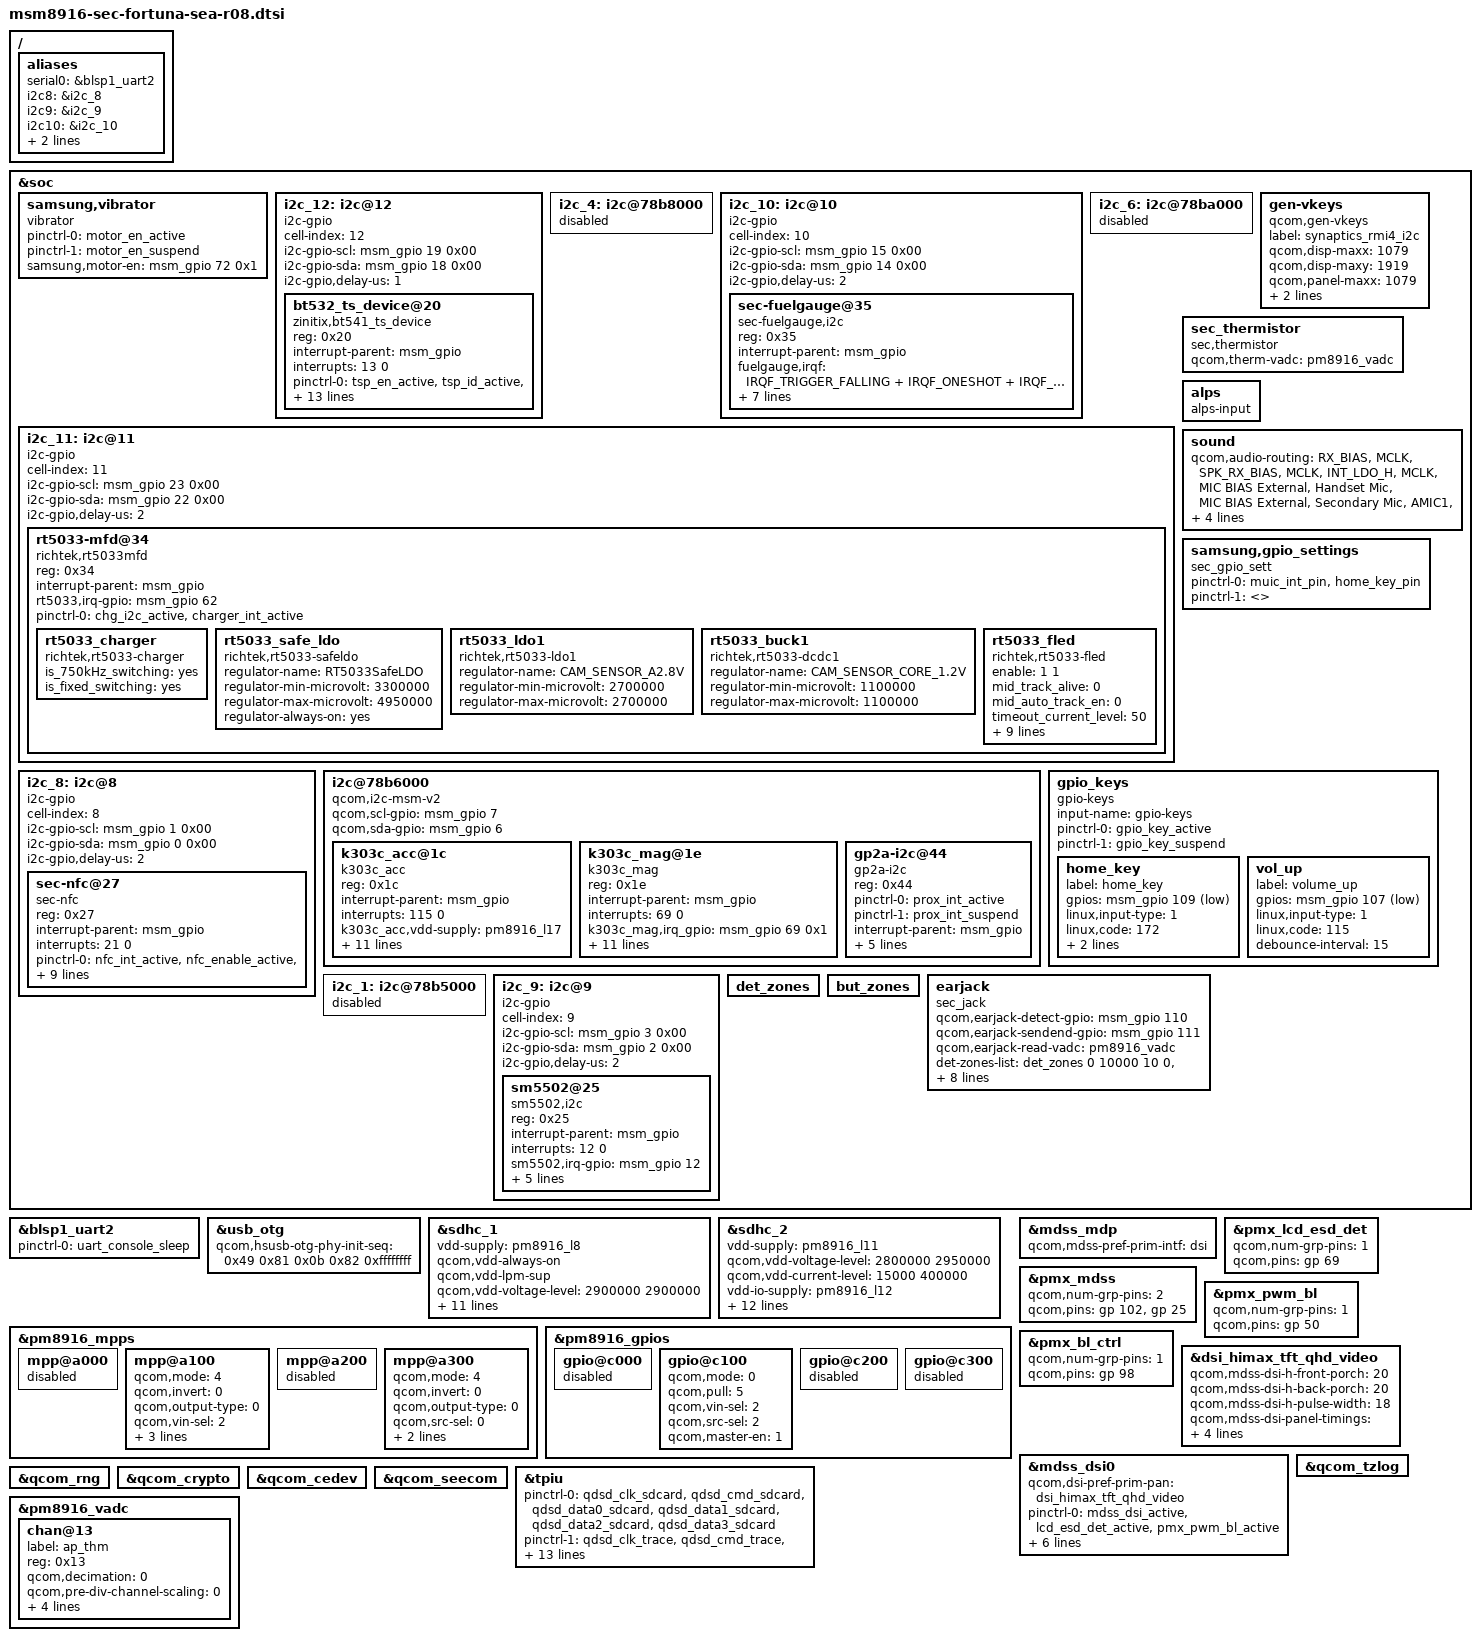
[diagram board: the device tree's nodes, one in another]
/* Copyright (c) 2014, The Linux Foundation. All rights reserved.
 *
 * This program is free software; you can redistribute it and/or modify
 * it under the terms of the GNU General Public License version 2 and
 * only version 2 as published by the Free Software Foundation.
 *
 * This program is distributed in the hope that it will be useful,
 * but WITHOUT ANY WARRANTY; without even the implied warranty of
 * MERCHANTABILITY or FITNESS FOR A PARTICULAR PURPOSE.  See the
 * GNU General Public License for more details.
 */

#include "msm8916.dtsi"
#include "msm8916-pinctrl-sec-fortuna-sea-r08.dtsi"
#include "dsi_panel_hx8389c_tft_qhd_video.dtsi"
#include "msm8916-camera.dtsi"
#include "msm8916-camera-sensor-cdp-r02.dtsi"
#include "msm8916-sec-fortuna-battery-r01.dtsi"

/ {
	aliases {
		serial0 = &blsp1_uart2;

		/*i2c-gpio bus_id*/
              //i2c7 = &i2c_7;
                i2c8 = &i2c_8;
		i2c9 = &i2c_9;
		i2c10 = &i2c_10;
		i2c11 = &i2c_11;
		i2c12 = &i2c_12;
	};
};

&soc {
	samsung,vibrator {
		pinctrl-names = "tlmm_motor_en_active","tlmm_motor_en_suspend";
		pinctrl-0 = <&motor_en_active>;
		pinctrl-1 = <&motor_en_suspend>;
		compatible = "vibrator";
		samsung,motor-en = <&msm_gpio 72 0x1>;
		status = "ok";
	};

	i2c_12:i2c@12 {
		cell-index = <12>;
		compatible = "i2c-gpio";
		i2c-gpio-scl = <&msm_gpio 19 0x00>;
		i2c-gpio-sda = <&msm_gpio 18 0x00>;
		i2c-gpio,delay-us = <1>;
		#address-cells = <1>;
		#size-cells = <0>;

		bt532_ts_device@20 {
			compatible = "zinitix,bt541_ts_device";
			reg = <0x20>;
			interrupt-parent = <&msm_gpio>;
			interrupts = <13 0>;
			pinctrl-names = "tsp_en_gpio_active", "tsp_en_gpio_suspend";
			pinctrl-0 = <&tsp_en_active &tsp_id_active &int_active &tsp_i2c_active>;
			pinctrl-1 = <&tsp_en_suspend &tsp_id_suspend &tsp_i2c_sleep>;
			vddo-supply = <&pm8916_l6>;
			zinitix,vdd_en-gpio = <&msm_gpio 73 0x01>;
			tsp_id-gpio =  <&msm_gpio 56 0x01>;
			zinitix,irq-gpio = <&msm_gpio 13 0x00>;
			zinitix,x_resolution = <540>;
			zinitix,y_resolution = <960>;
			zinitix,page_size = <128>;
			zinitix,orientation = <0>;
			zinitix,tsp_vdd_supply_type = <0>;
			zinitix,pname = "SM-G5308W";
		};
	};

	i2c_4: i2c@78b8000 { /* BLSP1 QUP4 */
		status="disable";
	};

       i2c_10:i2c@10 {
		cell-index = <10>;
		compatible = "i2c-gpio";
		i2c-gpio-scl = <&msm_gpio 15 0x00>;
		i2c-gpio-sda = <&msm_gpio 14 0x00>;
		i2c-gpio,delay-us = <2>;
		#address-cells = <1>;
		#size-cells = <0>;

		sec-fuelgauge@35{
			compatible = "sec-fuelgauge,i2c";
			reg = <0x35>;
			interrupt-parent = <&msm_gpio>;
			fuelgauge,irqf = "IRQF_TRIGGER_FALLING + IRQF_ONESHOT + IRQF_NO_SUSPEND";
			fuelgauge,fuel_int = <&msm_gpio 121 0x1>;
			pinctrl-names = "default";
			pinctrl-0 = <&fg_i2c_active &fuel_int_active>;

			fuelgauge,capacity_max = <1000>;
			fuelgauge,capacity_max_margin = <50>;
			fuelgauge,capacity_min = <0>;
			fuelgauge,capacity_calculation_type = <0x17>;
			fuelgauge,fuel_alert_soc = <1>;
		};
	};

	i2c_6: i2c@78ba000 { /* BLSP1 QUP6 */
		status="disable";
	};

       i2c_11:i2c@11 {
		cell-index = <11>;
		compatible = "i2c-gpio";
		i2c-gpio-scl = <&msm_gpio 23 0x00>;
		i2c-gpio-sda = <&msm_gpio 22 0x00>;
		i2c-gpio,delay-us = <2>;
		#address-cells = <1>;
		#size-cells = <0>;

		rt5033-mfd@34{
			compatible = "richtek,rt5033mfd";
			reg = <0x34>;
			interrupt-parent = <&msm_gpio>;
			rt5033,irq-gpio = <&msm_gpio 62 0x00>;
			pinctrl-names = "default";
			pinctrl-0 = <&chg_i2c_active &charger_int_active>;

			rt5033_charger {
				compatible = "richtek,rt5033-charger";
				is_750kHz_switching = "yes";
				is_fixed_switching = "yes";
			};

			rt5033_safe_ldo {
				compatible = "richtek,rt5033-safeldo";
				regulator-name = "RT5033SafeLDO"; /* constraints->name, change name by yourself*/
				regulator-min-microvolt = <3300000>;
				regulator-max-microvolt = <4950000>; /* if max == min then apply_uV = 1 */
				/* regulator-microvolt-offset = <0>; optional*/
				/* regulator-boot-on = "yes"; optional, exist = enabled */
				regulator-always-on = "yes";
				/* regulator-ramp-delay = <100>; optional*/
			};

			rt5033_ldo1 {
				compatible = "richtek,rt5033-ldo1";
				regulator-name = "CAM_SENSOR_A2.8V"; /* change name by yourself */
				regulator-min-microvolt = <2700000>;
				regulator-max-microvolt = <2700000>; /* max == min then apply_uV = 1 */
				/* regulator-microvolt-offset = < >; optional*/
				/* regulator-boot-on = "yes"; optional, exist = enabled */
				/* regulator-always-on = "yes"; optional, exist = enabled */
				/* regulator-ramp-delay = <100>; optional*/

			};


			rt5033_buck1 {
				compatible = "richtek,rt5033-dcdc1";
				regulator-name = "CAM_SENSOR_CORE_1.2V"; /* change name by yourself */
				regulator-min-microvolt = <1100000>;
				regulator-max-microvolt = <1100000>; /* max == min then apply_uV = 1 */
				/* regulator-microvolt-offset = < >; optional*/
				/* regulator-boot-on = "yes"; optional, exist = enabled */
				/* regulator-always-on = "yes"; optional, exist = enabled */
				/* regulator-ramp-delay = <100>; optional*/

			};

			rt5033_fled {
				compatible = "richtek,rt5033-fled";
				enable = <1 1>;
				mid_track_alive = <0>;
				mid_auto_track_en = <0>;
				timeout_current_level = <50>;
				strobe_current = <500>;
				strobe_timeout = <544>;
				torch_current = <63>;
				lv_protection = <3000>;
				mid_level = <4400>;
				rt5033,led1-gpio = <&msm_gpio 34 0x00>;
				rt5033,led2-gpio = <&msm_gpio 36 0x00>;
				pinctrl-names = "fled_default","fled_sleep";
				pinctrl-0 = <&cam_flash_active>;
				pinctrl-1 = <&cam_flash_sleep>;
			};
		};
	};

	gen-vkeys {
		compatible = "qcom,gen-vkeys";
		label = "synaptics_rmi4_i2c";
		qcom,disp-maxx = <1079>;
		qcom,disp-maxy = <1919>;
		qcom,panel-maxx = <1079>;
		qcom,panel-maxy = <2084>;
		qcom,key-codes = <158 139 172 217>;
	};

	sec_thermistor {
		compatible = "sec,thermistor";
		qcom,therm-vadc = <&pm8916_vadc>;
	};

	alps {
			compatible = "alps-input";
	};

	i2c_8: i2c@8 {
		cell-index = <8>;
		compatible = "i2c-gpio";
		i2c-gpio-scl = <&msm_gpio 1 0x00>;
		i2c-gpio-sda = <&msm_gpio 0 0x00>;
		i2c-gpio,delay-us = <2>;
		#address-cells = <1>;
		#size-cells = <0>;
		sec-nfc@27 {
			compatible = "sec-nfc";
			reg = <0x27>;
			interrupt-parent = <&msm_gpio>;
			interrupts = <21 0>;
			pinctrl-names = "default","nfc_suspend";
			pinctrl-0 = <&nfc_int_active &nfc_enable_active &nfc_firmware_active &nfc_i2c_active>;
			pinctrl-1 = <&nfc_int_suspend &nfc_enable_suspend &nfc_firmware_suspend &nfc_i2c_suspend>;
			sec-nfc,firm-gpio = <&msm_gpio 49 0x01>;
			sec-nfc,ven-gpio = <&msm_gpio 20 0x01>;
			sec-nfc,irq-gpio = <&msm_gpio 21 0x00>;
			clocks = <&clock_rpm clk_bb_clk2_pin>;
			clock-names = "nfc_clock";
			nfc_ldo-supply = <&pm8916_l14>;
		};
	};

	i2c@78b6000 { /* BLSP1 QUP2 */
		compatible = "qcom,i2c-msm-v2";
		qcom,scl-gpio = <&msm_gpio 7 0>;
		qcom,sda-gpio = <&msm_gpio 6 0>;
		k303c_acc@1c {
			compatible = "k303c_acc";
			reg = <0x1c>;
			interrupt-parent = <&msm_gpio>;
			interrupts = <115 0>;
			k303c_acc,vdd-supply = <&pm8916_l17>;
			k303c_acc,vio-supply = <&pm8916_l5>;
			k303c_acc,gpio_int1 = <&msm_gpio 115 0x00>;
			k303c_acc,poll_interval = <100>;
			k303c_acc,min_interval = <2>;
			k303c_acc,fs_range = <0x00>;
			k303c_acc,axis_map_x = <0>;
			k303c_acc,axis_map_y = <1>;
			k303c_acc,axis_map_z = <2>;
			k303c_acc,negate_x = <1>;
			k303c_acc,negate_y = <0>;
			k303c_acc,negate_z = <0>;
		};
		k303c_mag@1e {
			compatible = "k303c_mag";
			reg = <0x1e>;
			interrupt-parent = <&msm_gpio>;
			interrupts = <69 0>;
			k303c_mag,irq_gpio = <&msm_gpio 69 0x1>;
			k303c_mag,vdd-supply = <&pm8916_l17>;
			k303c_mag,vio-supply = <&pm8916_l5>;
			k303c_mag,poll_interval = <100>;
			k303c_mag,min_interval = <13>;
			k303c_mag,fs_range = <0x60>;
			k303c_mag,axis_map_x = <0>;
			k303c_mag,axis_map_y = <1>;
			k303c_mag,axis_map_z = <2>;
			k303c_mag,negate_x = <1>;
			k303c_mag,negate_y = <0>;
			k303c_mag,negate_z = <0>;
		};
		gp2a-i2c@44{
			compatible = "gp2a-i2c";
			reg = <0x44>;
			pinctrl-names = "default";
			pinctrl-0 = <&prox_int_active>;
			pinctrl-1 = <&prox_int_suspend>;
			interrupt-parent = <&msm_gpio>;
			interupts= <113 0>;
			gp2a-i2c,irq-gpio = <&msm_gpio 113 0x00>;
			gp2a-i2c,en-gpio = <&msm_gpio 8 0x00>;
			gp2a-vdd-supply = <&pm8916_l17>;
			gp2a-vio-supply = <&pm8916_l5>;
		};
	};

	/* Over-riding model specific changes */
	sound {
		qcom,audio-routing =
			"RX_BIAS", "MCLK",
			"SPK_RX_BIAS", "MCLK",
			"INT_LDO_H", "MCLK",
			"MIC BIAS External", "Handset Mic",
			"MIC BIAS External", "Secondary Mic",
			"AMIC1", "MIC BIAS External",
			"AMIC2", "Headset Mic",
			"AMIC3", "MIC BIAS External";
		pinctrl-names = "cdc_lines_act",
				"cdc_lines_sus";
		pinctrl-0 = <&cdc_pdm_lines_act>;
		pinctrl-1 = <&cdc_pdm_lines_sus>;
	};

	samsung,gpio_settings{
		compatible = "sec_gpio_sett";
		pinctrl-names = "sec_gpio_active","sec_gpio_suspend";
		pinctrl-0 = <&muic_int_pin &home_key_pin>;
		pinctrl-1 = <>;
	};

};

&blsp1_uart2 {
	status = "ok";
	pinctrl-names = "default";
	pinctrl-0 = <&uart_console_sleep>;
};

&soc {
	gpio_keys {
		compatible = "gpio-keys";
		input-name = "gpio-keys";
		pinctrl-names = "tlmm_gpio_key_active","tlmm_gpio_key_suspend";
		pinctrl-0 = <&gpio_key_active>;
		pinctrl-1 = <&gpio_key_suspend>;

		home_key {
			label = "home_key";
			gpios = <&msm_gpio 109 0x1>;
			linux,input-type = <1>;
			linux,code = <172>;
			gpio-key,wakeup;
			debounce-interval = <15>;
		};
		vol_up {
			label = "volume_up";
			gpios = <&msm_gpio 107 0x1>;
			linux,input-type = <1>;
			linux,code = <115>;
			debounce-interval = <15>;
		};
	};

	i2c_1: i2c@78b5000 { /* BLSP1 QUP1 */
		status="disable";
	};

	i2c_9:i2c@9 { /*SM5502 GPIO-I2C*/
		cell-index = <9>;
		compatible = "i2c-gpio";
		i2c-gpio-scl = <&msm_gpio 3 0x00>;
		i2c-gpio-sda = <&msm_gpio 2 0x00>;
		i2c-gpio,delay-us = <2>;
		#address-cells = <1>;
		#size-cells = <0>;

		sm5502@25{
			compatible = "sm5502,i2c";
			reg = <0x25>;
			interrupt-parent = <&msm_gpio>;
			interrupts= <12 0>;
			sm5502,irq-gpio = <&msm_gpio 12 0x00>;
			sm5502,gpio-sda = <&msm_gpio 2 0x00>;
			sm5502,gpio-scl = <&msm_gpio 3 0x00>;
			sm5502,uarton-gpio = <&msm_gpio 114 0x00>;
			pinctrl-names = "sm5502_i2c_active","sm5502_i2c_suspend";
			pinctrl-0 = <&muic_i2c_active>;
			pinctrl-1 = <&muic_i2c_suspend>;
		};
	};

	det_zones: det_zones {
		#list-det-cells = <4>;
	};

	but_zones: but_zones {
		#list-but-cells = <3>;
	};

	earjack {
		compatible = "sec_jack";
		qcom,earjack-detect-gpio = <&msm_gpio 110 0x0>;
		qcom,earjack-sendend-gpio = <&msm_gpio 111 0x0>;
		qcom,earjack-read-vadc = <&pm8916_vadc>;

		det-zones-list = <&det_zones 0 10000 10 0>,
						 <&det_zones 975 10000 10 0>,
						 <&det_zones 976 10000 10 1>,
						 <&det_zones 1810 10000 10 1>;
		but-zones-list = <&but_zones 0 0 325>,
						 <&but_zones 1 326 457>,
						 <&but_zones 2 458 999>;
		mpp-channel-scaling = <2 1 1>;
		pinctrl-names = "earjack_gpio_active","earjack_gpio_suspend";
		pinctrl-0 = <&earjack_det_act &earjack_switch_act>;
		pinctrl-1 = <&earjack_det_sus &earjack_switch_sus>;
	};
};

&usb_otg {
	qcom,hsusb-otg-phy-init-seq =
					<0x49 0x81 0x0b 0x82 0xffffffff>;
};

&sdhc_1 {
	vdd-supply = <&pm8916_l8>;
	qcom,vdd-always-on;
	qcom,vdd-lpm-sup;
	qcom,vdd-voltage-level = <2900000 2900000>;
	qcom,vdd-current-level = <200 400000>;

	vdd-io-supply = <&pm8916_l5>;
	qcom,vdd-io-always-on;
	qcom,vdd-io-lpm-sup;
	qcom,vdd-io-voltage-level = <1800000 1800000>;
	qcom,vdd-io-current-level = <200 60000>;

	pinctrl-names = "active", "sleep";
	pinctrl-0 = <&sdc1_clk_on &sdc1_cmd_on &sdc1_data_on>;
	pinctrl-1 = <&sdc1_clk_off &sdc1_cmd_off &sdc1_data_off>;

	qcom,nonremovable;

	status = "ok";
};

&sdhc_2 {
	vdd-supply = <&pm8916_l11>;
	qcom,vdd-voltage-level = <2800000 2950000>;
	qcom,vdd-current-level = <15000 400000>;

	vdd-io-supply = <&pm8916_l12>;
	qcom,vdd-io-voltage-level = <1800000 2950000>;
	qcom,vdd-io-current-level = <200 50000>;

	pinctrl-names = "active", "sleep";
	pinctrl-0 = <&sdc2_clk_on &sdc2_cmd_on &sdc2_data_on &sdc2_cd_on>;
	pinctrl-1 = <&sdc2_clk_off &sdc2_cmd_off &sdc2_data_off &sdc2_cd_off>;

	#address-cells = <0>;
	interrupt-parent = <&sdhc_2>;
	interrupts = <0 1 2>;
	#interrupt-cells = <1>;
	interrupt-map-mask = <0xffffffff>;
	interrupt-map = <0 &intc 0 125 0
			1 &intc 0 221 0
			2 &msm_gpio 38 0>;
	interrupt-names = "hc_irq", "pwr_irq", "status_irq";
	cd-gpios = <&msm_gpio 38 0x1>;

	status = "ok";
};

&pm8916_mpps {
	mpp@a000 { /* MPP 1 */
		/* VDD_PX */
		status = "disabled";
	};

	mpp@a100 { /* MPP 2 */
		status = "ok";
		qcom,mode = <4>; // AIN input
		qcom,invert = <0>; //No Invert
		qcom,output-type = <0>; //CMOS
		qcom,vin-sel = <2>; //PM8971_S3 1.8v
		qcom,src-sel = <0>; //MPP Constant
		qcom,ain-route = <1>; // QPNP_PIN_AIN_AMUX_CH6 = 1 for MPP2
		qcom,master-en = <1>; // Function constant
	};

	mpp@a200 { /* MPP 3 */
		/* VREF DAC */
		status = "disabled";
	};

	mpp@a300 { /* MPP 4 */
		status = "ok";
		qcom,mode = <4>; // AIN input
		qcom,invert = <0>; //No Invert
		qcom,output-type = <0>; //CMOS
		qcom,src-sel = <0>; //MPP Constant
		qcom,ain-route = <3>; // QPNP_PIN_AIN_AMUX_CH8 = 3 for MPP4
		qcom,master-en = <1>; // Function constant
	};
};

&pm8916_gpios {
	gpio@c000 { /* GPIO 1 */
		/* Battery UICC Alarm */
		status = "disabled";
	};

	gpio@c100 { /* GPIO 2 */
		/* NFC_CLK_REQ */
		qcom,mode = <0>; /* QPNP_PIN_MODE_DIG_IN */
		qcom,pull = <5>; /* QPNP_PIN_PULL_NO */
		qcom,vin-sel = <2>; /* QPNP_PIN_VIN2 */
		qcom,src-sel = <2>; /* QPNP_PIN_SEL_FUNC_1 */
		qcom,master-en = <1>;
	};

	gpio@c200 { /* GPIO 3 */
		/* External regulator control for WTR */
		status = "disabled";
	};

	gpio@c300 { /* GPIO 4 */
		/* External regulator control for APC */
		status = "disabled";
	};
};

&mdss_mdp {
       qcom,mdss-pref-prim-intf = "dsi";
};

&pmx_lcd_esd_det {
	qcom,num-grp-pins = <1>;
	qcom,pins = <&gp 69>;
};

&pmx_mdss {
                 qcom,num-grp-pins = <2>;
                 qcom,pins = <&gp 102>, <&gp 25>;
};

&pmx_pwm_bl {
                 qcom,num-grp-pins = <1>;
                 qcom,pins = <&gp 50>;
};

&pmx_bl_ctrl {
                 qcom,num-grp-pins = <1>;
                 qcom,pins = <&gp 98>;
};

&dsi_himax_tft_qhd_video {
	qcom,mdss-dsi-h-front-porch = <20>;
	qcom,mdss-dsi-h-back-porch = <20>;
	qcom,mdss-dsi-h-pulse-width = <18>;
	qcom,mdss-dsi-panel-timings = [7B 1A 10 00 3E 40 16 1E 15 03 04 00];
	qcom,mdss-dsi-t-clk-pre = <0x1A>;
	qcom,mdss-dsi-on-command = [39 01 00 00 0A 00 04 B9 FF 83 89
				39 01 00 00 00 00 15 B1 7F 10 10 D2 32 80 10 F0 56 80 20 20 F8 AA AA A1 00 80 30 00
				39 01 00 00 00 00 0B B2 82 50 05 07 F0 38 11 64 5D 09
				39 01 00 00 00 00 0C B4 66 66 66 70 00 00 18 76 28 76 A8
				39 01 00 00 00 00 02 D2 33
				39 01 00 00 00 00 05 C0 30 17 00 03
				39 01 00 00 00 00 05 C7 00 80 00 C0
				39 01 00 00 0A 00 05 BF 05 50 00 3E
				39 01 00 00 00 00 04 B9 FF 83 89
				39 01 00 00 00 00 02 CC 0E
				39 01 00 00 00 00 24 D3 00 00 00 00 00 08 00 32 10 00 00 00 03 C6 03 C6 00 00 00 00 35 33 04 04 37 00 00 00 05 08 00 00 0A 00 01
				39 01 00 00 00 00 27 D5 18 18 18 18 19 19 18 18 20 21 24 25 18 18 18 18 00 01 04 05 02 03 06 07 18 18 18 18 18 18 18 18 18 18 18 18 18 18
				39 01 00 00 00 00 27 D6 18 18 18 18 18 18 19 19 25 24 21 20 18 18 18 18 07 06 03 02 05 04 01 00 18 18 18 18 18 18 18 18 18 18 18 18 18 18
				39 01 00 00 00 00 04 B7 20 80 00
				39 01 00 00 00 00 2B E0 00 02 06 38 3C 3F 1B 46 06 09 0C 17 10 13 16 13 14 08 13 15 19 00 02 06 37 3C 3F 1A 45 05 09 0B 16 0F 13 15 13 14 07 12 14 18
				39 01 00 00 00 00 02 BD 00
				39 01 00 00 00 00 2C C1 01 00 0B 12 19 21 28 31 3A 42 49 50 58 60 68 70 78 80 88 8F 97 9E A6 AD B5 BC C4 CC D4 DC E4 EC F3 F8 00 00 00 00 00 00 00 00 00
				39 01 00 00 00 00 02 BD 01
				39 01 00 00 00 00 2B C1 00 06 0E 17 1F 26 2F 37 40 47 4E 56 5E 66 6E 75 7D 85 8C 94 9C A3 AA B1 B8 BF C8 D0 D7 DF E6 ED F4 00 00 00 00 00 00 00 00 00
				39 01 00 00 00 00 02 BD 02
				39 01 00 00 00 00 2B C1 00 09 12 1B 23 2A 34 3D 45 4D 54 5D 65 6D 76 7E 86 8E 96 9E A5 AE B5 BC C4 CC D4 DC E4 EB F2 F9 FF 00 00 00 00 00 00 00 00 00
				/*CABC Begin*/
				39 01 00 00 05 00 0E C9 1F 00 0F 1E 81 1E 00 00 01 19 00 00 20  /* CABC PWM output to 25Khz*/
				39 01 00 00 05 00 02 55 00			/*Turn off CABC*/
				39 01 00 00 05 00 02 53 24 /*Enable Backlight Control */
				/* CABC end*/
				05 01 00 00 7D 00 02 11 00
				05 01 00 00 05 00 02 29 00
					];
};

&mdss_dsi0 {
	qcom,dsi-pref-prim-pan = <&dsi_himax_tft_qhd_video>;
	pinctrl-names = "mdss_default", "mdss_sleep";
	pinctrl-0 = <&mdss_dsi_active &lcd_esd_det_active &pmx_pwm_bl_active>;
	pinctrl-1 = <&mdss_dsi_suspend &lcd_esd_det_suspend &pmx_pwm_bl_suspend &pmx_bl_ctrl_suspend>;
	qcom,platform-reset-gpio = <&msm_gpio 25 0>;
	qcom,platform-bklight-en-gpio = <&msm_gpio 98 0>;
	qcom,platform-enable-gpio = <&msm_gpio 102 0>;
};

&qcom_tzlog {
	status = "okay";
};

&qcom_rng {
	status = "okay";
};

&qcom_crypto {
	status = "okay";
};

&qcom_cedev {
	status = "okay";
};

&qcom_seecom {
	status = "okay";
};

/* CoreSight */
&tpiu {
      pinctrl-names = "sdcard", "trace", "swduart",
		      "swdtrc", "jtag", "spmi";
       /* NIDnT */
      pinctrl-0 = <&qdsd_clk_sdcard &qdsd_cmd_sdcard
                  &qdsd_data0_sdcard &qdsd_data1_sdcard
                  &qdsd_data2_sdcard &qdsd_data3_sdcard>;
      pinctrl-1 = <&qdsd_clk_trace &qdsd_cmd_trace
                  &qdsd_data0_trace &qdsd_data1_trace
                  &qdsd_data2_trace &qdsd_data3_trace>;
      pinctrl-2 = <&qdsd_cmd_swduart &qdsd_data0_swduart
                  &qdsd_data1_swduart &qdsd_data2_swduart
                  &qdsd_data3_swduart>;
      pinctrl-3 = <&qdsd_clk_swdtrc &qdsd_cmd_swdtrc
                  &qdsd_data0_swdtrc &qdsd_data1_swdtrc
                  &qdsd_data2_swdtrc &qdsd_data3_swdtrc>;
      pinctrl-4 = <&qdsd_cmd_jtag &qdsd_data0_jtag
                  &qdsd_data1_jtag &qdsd_data2_jtag
                  &qdsd_data3_jtag>;
      pinctrl-5 = <&qdsd_clk_spmi &qdsd_cmd_spmi
                  &qdsd_data0_spmi &qdsd_data3_spmi>;
};

&pm8916_vadc {
	chan@13 {
		label = "ap_thm";
		reg = <0x13>; // channel 19 for MPP4 , 1:1scale
		qcom,decimation = <0>;
		qcom,pre-div-channel-scaling = <0>; // 1:1scale
		qcom,calibration-type = "ratiometric";
		qcom,scale-function = <1>;
		qcom,hw-settle-time = <2>;
		qcom,fast-avg-setup = <0>;
	};
};
